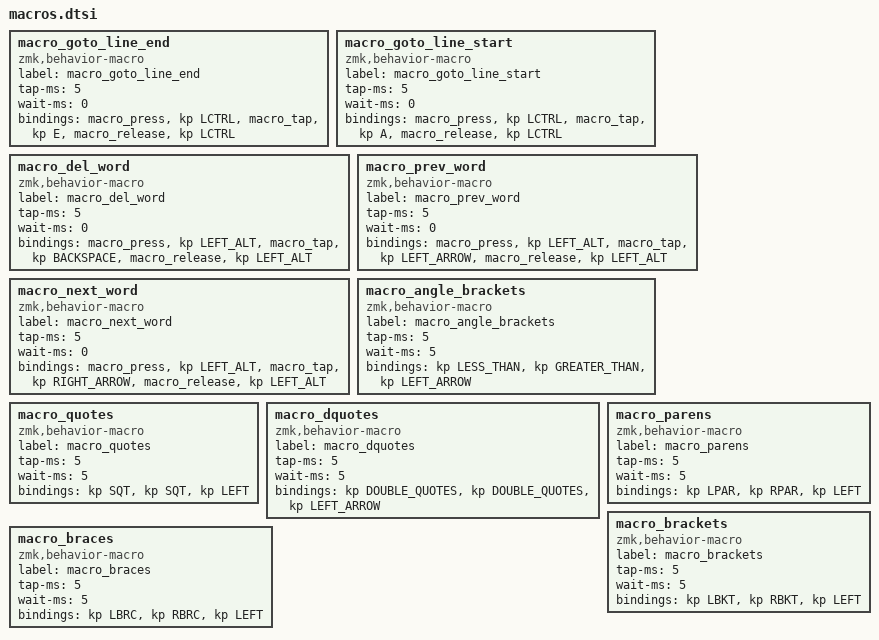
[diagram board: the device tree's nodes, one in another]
macro_goto_line_end: macro_goto_line_end{
compatible = "zmk,behavior-macro";
label = "macro_goto_line_end";
tap-ms = <5>;
wait-ms = <0>;
#binding-cells = <0>;
bindings = <&macro_press &kp LCTRL>, <&macro_tap &kp E>, <&macro_release &kp LCTRL>;
};
macro_goto_line_start: macro_goto_line_start{
compatible = "zmk,behavior-macro";
label = "macro_goto_line_start";
tap-ms = <5>;
wait-ms = <0>;
#binding-cells = <0>;
bindings = <&macro_press &kp LCTRL>, <&macro_tap &kp A>, <&macro_release &kp LCTRL>;
};
macro_del_word: macro_del_word{
compatible = "zmk,behavior-macro";
label = "macro_del_word";
tap-ms = <5>;
wait-ms = <0>;
#binding-cells = <0>;
bindings = <&macro_press &kp LEFT_ALT>, <&macro_tap &kp BACKSPACE>, <&macro_release &kp LEFT_ALT>;
};
macro_prev_word: macro_prev_word{
compatible = "zmk,behavior-macro";
label = "macro_prev_word";
tap-ms = <5>;
wait-ms = <0>;
#binding-cells = <0>;
bindings = <&macro_press &kp LEFT_ALT>, <&macro_tap &kp LEFT_ARROW>, <&macro_release &kp LEFT_ALT>;
};
macro_next_word: macro_next_word{
compatible = "zmk,behavior-macro";
label = "macro_next_word";
tap-ms = <5>;
wait-ms = <0>;
#binding-cells = <0>;
bindings = <&macro_press &kp LEFT_ALT>, <&macro_tap &kp RIGHT_ARROW>, <&macro_release &kp LEFT_ALT>;
};
macro_angle_brackets: macro_angle_brackets{
compatible = "zmk,behavior-macro";
label = "macro_angle_brackets";
#binding-cells = <0>;
tap-ms = <5>;
wait-ms = <5>;
bindings = <&kp LESS_THAN>, <&kp GREATER_THAN>, <&kp LEFT_ARROW>;
};
macro_quotes: macro_quotes{
compatible = "zmk,behavior-macro";
label = "macro_quotes";
#binding-cells = <0>;
tap-ms = <5>;
wait-ms = <5>;
bindings = <&kp SQT>, <&kp SQT>, <&kp LEFT>;
};
macro_dquotes: macro_dquotes{
compatible = "zmk,behavior-macro";
label = "macro_dquotes";
#binding-cells = <0>;
tap-ms = <5>;
wait-ms = <5>;
bindings = <&kp DOUBLE_QUOTES>, <&kp DOUBLE_QUOTES>, <&kp LEFT_ARROW>;
};
macro_parens: macro_parens{
compatible = "zmk,behavior-macro";
label = "macro_parens";
#binding-cells = <0>;
tap-ms = <5>;
wait-ms = <5>;
bindings = <&kp LPAR>, <&kp RPAR>, <&kp LEFT>;
};
macro_brackets: macro_brackets{
compatible = "zmk,behavior-macro";
label = "macro_brackets";
#binding-cells = <0>;
tap-ms = <5>;
wait-ms = <5>;
bindings = <&kp LBKT>, <&kp RBKT>, <&kp LEFT>;
};
macro_braces: macro_braces{
compatible = "zmk,behavior-macro";
label = "macro_braces";
#binding-cells = <0>;
tap-ms = <5>;
wait-ms = <5>;
bindings = <&kp LBRC>, <&kp RBRC>, <&kp LEFT>;
};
